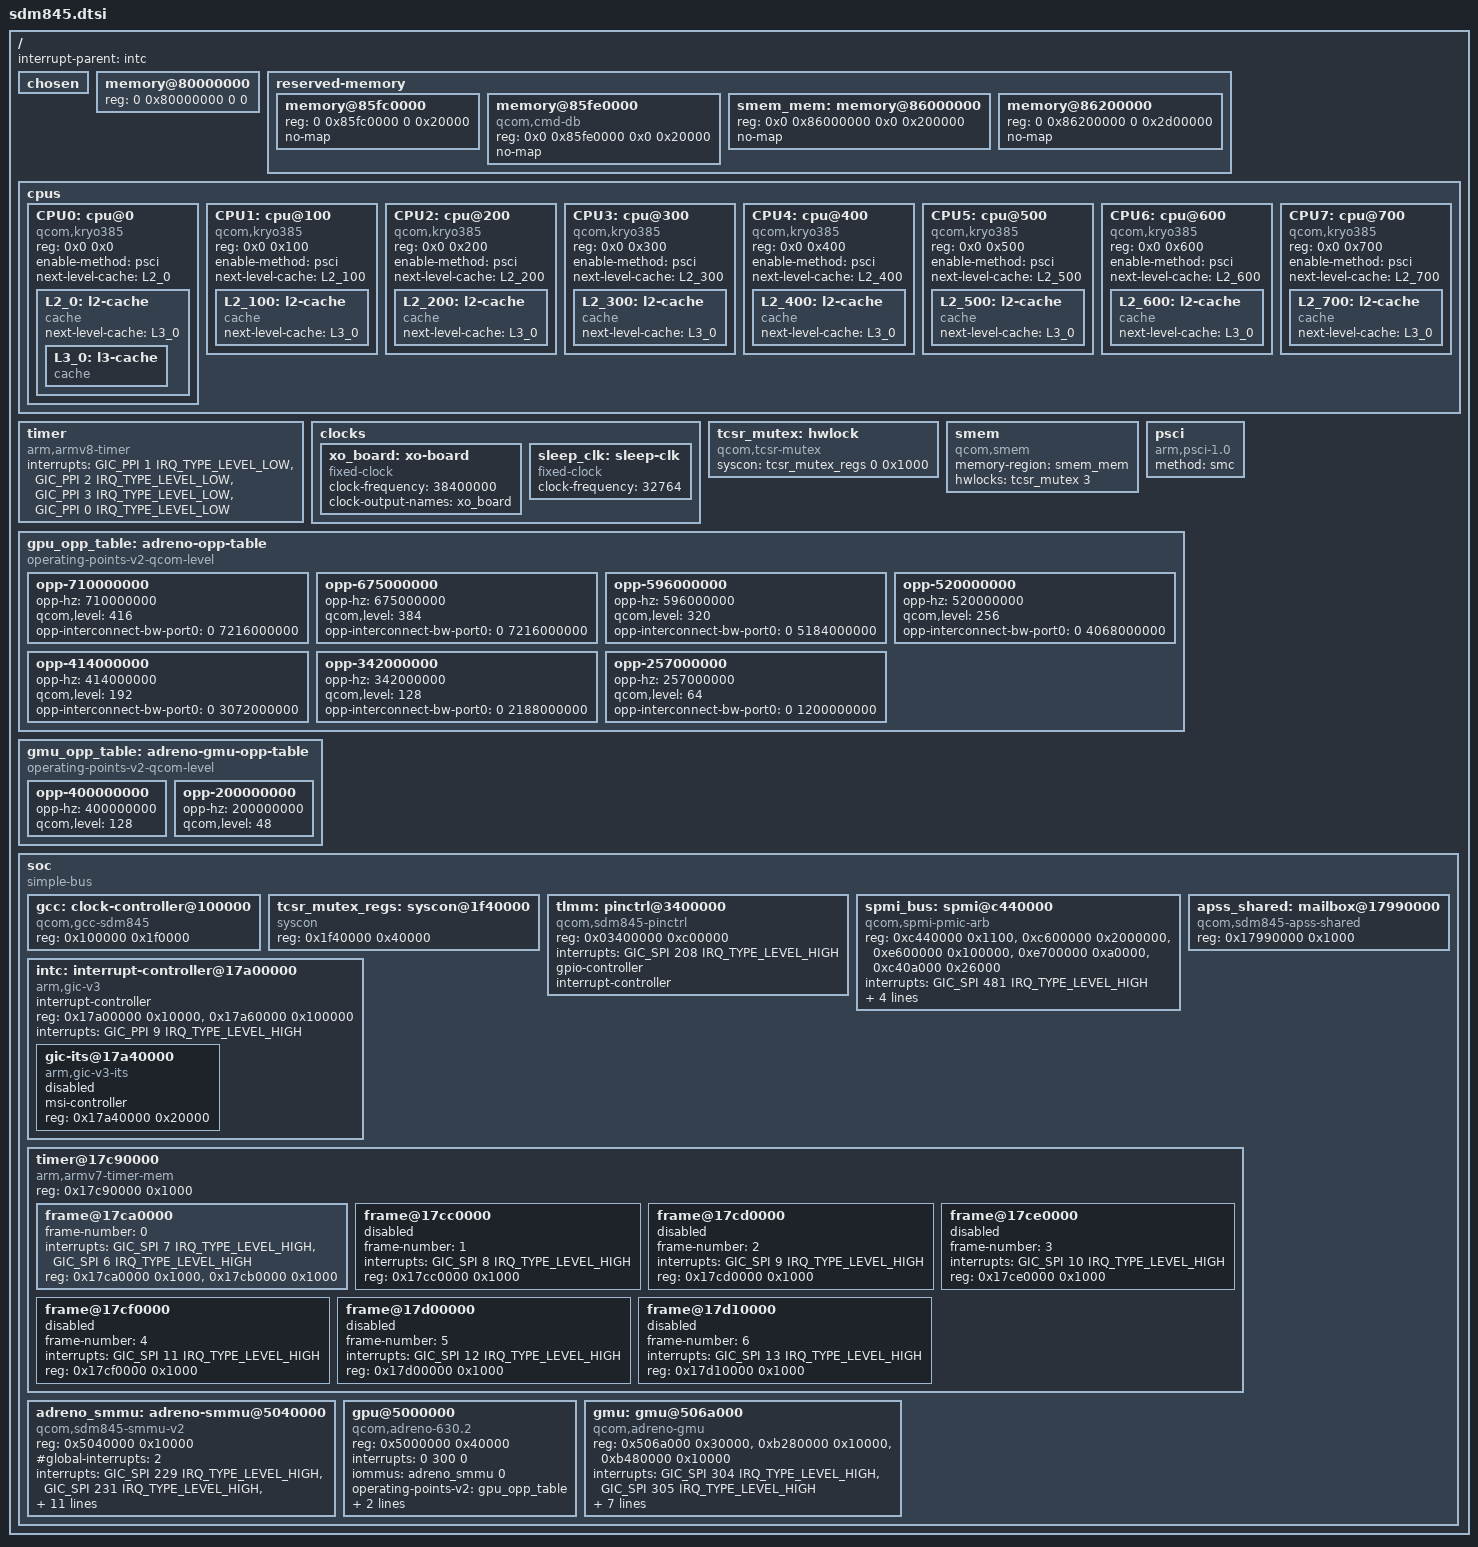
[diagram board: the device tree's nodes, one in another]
// SPDX-License-Identifier: GPL-2.0
/*
 * SDM845 SoC device tree source
 *
 * Copyright (c) 2018, The Linux Foundation. All rights reserved.
 */

#include <dt-bindings/interrupt-controller/arm-gic.h>

/ {
	interrupt-parent = <&intc>;

	#address-cells = <2>;
	#size-cells = <2>;

	chosen { };

	memory@80000000 {
		device_type = "memory";
		/* We expect the bootloader to fill in the size */
		reg = <0 0x80000000 0 0>;
	};

	reserved-memory {
		#address-cells = <2>;
		#size-cells = <2>;
		ranges;

		memory@85fc0000 {
			reg = <0 0x85fc0000 0 0x20000>;
			no-map;
		};

		memory@85fe0000 {
			compatible = "qcom,cmd-db";
			reg = <0x0 0x85fe0000 0x0 0x20000>;
			no-map;
		};

		smem_mem: memory@86000000 {
			reg = <0x0 0x86000000 0x0 0x200000>;
			no-map;
		};

		memory@86200000 {
			reg = <0 0x86200000 0 0x2d00000>;
			no-map;
		};
	};

	cpus {
		#address-cells = <2>;
		#size-cells = <0>;

		CPU0: cpu@0 {
			device_type = "cpu";
			compatible = "qcom,kryo385";
			reg = <0x0 0x0>;
			enable-method = "psci";
			next-level-cache = <&L2_0>;
			L2_0: l2-cache {
				compatible = "cache";
				next-level-cache = <&L3_0>;
				L3_0: l3-cache {
				      compatible = "cache";
				};
			};
		};

		CPU1: cpu@100 {
			device_type = "cpu";
			compatible = "qcom,kryo385";
			reg = <0x0 0x100>;
			enable-method = "psci";
			next-level-cache = <&L2_100>;
			L2_100: l2-cache {
				compatible = "cache";
				next-level-cache = <&L3_0>;
			};
		};

		CPU2: cpu@200 {
			device_type = "cpu";
			compatible = "qcom,kryo385";
			reg = <0x0 0x200>;
			enable-method = "psci";
			next-level-cache = <&L2_200>;
			L2_200: l2-cache {
				compatible = "cache";
				next-level-cache = <&L3_0>;
			};
		};

		CPU3: cpu@300 {
			device_type = "cpu";
			compatible = "qcom,kryo385";
			reg = <0x0 0x300>;
			enable-method = "psci";
			next-level-cache = <&L2_300>;
			L2_300: l2-cache {
				compatible = "cache";
				next-level-cache = <&L3_0>;
			};
		};

		CPU4: cpu@400 {
			device_type = "cpu";
			compatible = "qcom,kryo385";
			reg = <0x0 0x400>;
			enable-method = "psci";
			next-level-cache = <&L2_400>;
			L2_400: l2-cache {
				compatible = "cache";
				next-level-cache = <&L3_0>;
			};
		};

		CPU5: cpu@500 {
			device_type = "cpu";
			compatible = "qcom,kryo385";
			reg = <0x0 0x500>;
			enable-method = "psci";
			next-level-cache = <&L2_500>;
			L2_500: l2-cache {
				compatible = "cache";
				next-level-cache = <&L3_0>;
			};
		};

		CPU6: cpu@600 {
			device_type = "cpu";
			compatible = "qcom,kryo385";
			reg = <0x0 0x600>;
			enable-method = "psci";
			next-level-cache = <&L2_600>;
			L2_600: l2-cache {
				compatible = "cache";
				next-level-cache = <&L3_0>;
			};
		};

		CPU7: cpu@700 {
			device_type = "cpu";
			compatible = "qcom,kryo385";
			reg = <0x0 0x700>;
			enable-method = "psci";
			next-level-cache = <&L2_700>;
			L2_700: l2-cache {
				compatible = "cache";
				next-level-cache = <&L3_0>;
			};
		};
	};

	timer {
		compatible = "arm,armv8-timer";
		interrupts = <GIC_PPI 1 IRQ_TYPE_LEVEL_LOW>,
			     <GIC_PPI 2 IRQ_TYPE_LEVEL_LOW>,
			     <GIC_PPI 3 IRQ_TYPE_LEVEL_LOW>,
			     <GIC_PPI 0 IRQ_TYPE_LEVEL_LOW>;
	};

	clocks {
		xo_board: xo-board {
			compatible = "fixed-clock";
			#clock-cells = <0>;
			clock-frequency = <38400000>;
			clock-output-names = "xo_board";
		};

		sleep_clk: sleep-clk {
			compatible = "fixed-clock";
			#clock-cells = <0>;
			clock-frequency = <32764>;
		};
	};

	tcsr_mutex: hwlock {
		compatible = "qcom,tcsr-mutex";
		syscon = <&tcsr_mutex_regs 0 0x1000>;
		#hwlock-cells = <1>;
	};

	smem {
		compatible = "qcom,smem";
		memory-region = <&smem_mem>;
		hwlocks = <&tcsr_mutex 3>;
	};

	psci {
		compatible = "arm,psci-1.0";
		method = "smc";
	};

gpu_opp_table: adreno-opp-table {
		compatible = "operating-points-v2-qcom-level";

		opp-710000000 {
			opp-hz = /bits/ 64 <710000000>;
			qcom,level = <416>;
			opp-interconnect-bw-port0 = /bits/ 64 <0 7216000000>;
		};

		opp-675000000 {
			opp-hz = /bits/ 64 <675000000>;
			qcom,level = <384>;
			opp-interconnect-bw-port0 = /bits/ 64 <0 7216000000>;
		};

		opp-596000000 {
			opp-hz = /bits/ 64 <596000000>;
			qcom,level = <320>;
			opp-interconnect-bw-port0 = /bits/ 64 <0 5184000000>;
		};

		opp-520000000 {
			opp-hz = /bits/ 64 <520000000>;
			qcom,level = <256>;
			opp-interconnect-bw-port0 = /bits/ 64 <0 4068000000>;
		};

		opp-414000000 {
			opp-hz = /bits/ 64 <414000000>;
			qcom,level = <192>;
			opp-interconnect-bw-port0 = /bits/ 64 <0 3072000000>;
		};

		opp-342000000 {
			opp-hz = /bits/ 64 <342000000>;
			qcom,level = <128>;
			opp-interconnect-bw-port0 = /bits/ 64 <0 2188000000>;
		};

		opp-257000000 {
			opp-hz = /bits/ 64 <257000000>;
			qcom,level = <64>;
			opp-interconnect-bw-port0 = /bits/ 64 <0 1200000000>;
		};
	};

	gmu_opp_table: adreno-gmu-opp-table {
		compatible = "operating-points-v2-qcom-level";

		opp-400000000 {
			opp-hz = /bits/ 64 <400000000>;
			qcom,level = <128>;
		};

		opp-200000000 {
			opp-hz = /bits/ 64 <200000000>;
			qcom,level = <48>;
		};
	};

	soc: soc {
		#address-cells = <1>;
		#size-cells = <1>;
		ranges = <0 0 0 0xffffffff>;
		compatible = "simple-bus";

		gcc: clock-controller@100000 {
			compatible = "qcom,gcc-sdm845";
			reg = <0x100000 0x1f0000>;
			#clock-cells = <1>;
			#reset-cells = <1>;
			#power-domain-cells = <1>;
		};

		tcsr_mutex_regs: syscon@1f40000 {
			compatible = "syscon";
			reg = <0x1f40000 0x40000>;
		};

		tlmm: pinctrl@3400000 {
			compatible = "qcom,sdm845-pinctrl";
			reg = <0x03400000 0xc00000>;
			interrupts = <GIC_SPI 208 IRQ_TYPE_LEVEL_HIGH>;
			gpio-controller;
			#gpio-cells = <2>;
			interrupt-controller;
			#interrupt-cells = <2>;
		};

		spmi_bus: spmi@c440000 {
			compatible = "qcom,spmi-pmic-arb";
			reg = <0xc440000 0x1100>,
			      <0xc600000 0x2000000>,
			      <0xe600000 0x100000>,
			      <0xe700000 0xa0000>,
			      <0xc40a000 0x26000>;
			reg-names = "core", "chnls", "obsrvr", "intr", "cnfg";
			interrupt-names = "periph_irq";
			interrupts = <GIC_SPI 481 IRQ_TYPE_LEVEL_HIGH>;
			qcom,ee = <0>;
			qcom,channel = <0>;
			#address-cells = <2>;
			#size-cells = <0>;
			interrupt-controller;
			#interrupt-cells = <4>;
			cell-index = <0>;
		};

		apss_shared: mailbox@17990000 {
			compatible = "qcom,sdm845-apss-shared";
			reg = <0x17990000 0x1000>;
			#mbox-cells = <1>;
		};

		intc: interrupt-controller@17a00000 {
			compatible = "arm,gic-v3";
			#address-cells = <1>;
			#size-cells = <1>;
			ranges;
			#interrupt-cells = <3>;
			interrupt-controller;
			reg = <0x17a00000 0x10000>,     /* GICD */
			      <0x17a60000 0x100000>;    /* GICR * 8 */
			interrupts = <GIC_PPI 9 IRQ_TYPE_LEVEL_HIGH>;

			gic-its@17a40000 {
				compatible = "arm,gic-v3-its";
				msi-controller;
				#msi-cells = <1>;
				reg = <0x17a40000 0x20000>;
				status = "disabled";
			};
		};

		timer@17c90000 {
			#address-cells = <1>;
			#size-cells = <1>;
			ranges;
			compatible = "arm,armv7-timer-mem";
			reg = <0x17c90000 0x1000>;

			frame@17ca0000 {
				frame-number = <0>;
				interrupts = <GIC_SPI 7 IRQ_TYPE_LEVEL_HIGH>,
					     <GIC_SPI 6 IRQ_TYPE_LEVEL_HIGH>;
				reg = <0x17ca0000 0x1000>,
				      <0x17cb0000 0x1000>;
			};

			frame@17cc0000 {
				frame-number = <1>;
				interrupts = <GIC_SPI 8 IRQ_TYPE_LEVEL_HIGH>;
				reg = <0x17cc0000 0x1000>;
				status = "disabled";
			};

			frame@17cd0000 {
				frame-number = <2>;
				interrupts = <GIC_SPI 9 IRQ_TYPE_LEVEL_HIGH>;
				reg = <0x17cd0000 0x1000>;
				status = "disabled";
			};

			frame@17ce0000 {
				frame-number = <3>;
				interrupts = <GIC_SPI 10 IRQ_TYPE_LEVEL_HIGH>;
				reg = <0x17ce0000 0x1000>;
				status = "disabled";
			};

			frame@17cf0000 {
				frame-number = <4>;
				interrupts = <GIC_SPI 11 IRQ_TYPE_LEVEL_HIGH>;
				reg = <0x17cf0000 0x1000>;
				status = "disabled";
			};

			frame@17d00000 {
				frame-number = <5>;
				interrupts = <GIC_SPI 12 IRQ_TYPE_LEVEL_HIGH>;
				reg = <0x17d00000 0x1000>;
				status = "disabled";
			};

			frame@17d10000 {
				frame-number = <6>;
				interrupts = <GIC_SPI 13 IRQ_TYPE_LEVEL_HIGH>;
				reg = <0x17d10000 0x1000>;
				status = "disabled";
			};
		};

		adreno_smmu: adreno-smmu@5040000 {
			compatible = "qcom,sdm845-smmu-v2", "qcom,smmu-v2";
			reg = <0x5040000 0x10000>;
			#iommu-cells = <1>;
			#global-interrupts = <2>;
			interrupts = <GIC_SPI 229 IRQ_TYPE_LEVEL_HIGH>,
					<GIC_SPI 231 IRQ_TYPE_LEVEL_HIGH>,
					<GIC_SPI 364 IRQ_TYPE_EDGE_RISING>,
					<GIC_SPI 365 IRQ_TYPE_EDGE_RISING>,
					<GIC_SPI 366 IRQ_TYPE_EDGE_RISING>,
					<GIC_SPI 367 IRQ_TYPE_EDGE_RISING>,
					<GIC_SPI 368 IRQ_TYPE_EDGE_RISING>,
					<GIC_SPI 369 IRQ_TYPE_EDGE_RISING>,
					<GIC_SPI 370 IRQ_TYPE_EDGE_RISING>,
					<GIC_SPI 371 IRQ_TYPE_EDGE_RISING>;
			clocks = <&gcc GCC_GPU_MEMNOC_GFX_CLK>,
				<&gcc GCC_GPU_CFG_AHB_CLK>;
			clock-names = "bus", "iface";

			power-domains = <&gpucc GPU_CX_GDSC>;
		};

		gpu@5000000 {
			compatible = "qcom,adreno-630.2", "qcom,adreno";
			#stream-id-cells = <16>;

			reg = <0x5000000 0x40000>;
			reg-names = "kgsl_3d0_reg_memory";

			/*
			 * Look ma, no clocks! The GPU clocks and power are
			 * controlled entirely by the GMU
			 */

			interrupts = <0 300 0>;
			interrupt-names = "kgsl_3d0_irq";

			iommus = <&adreno_smmu 0>;

			operating-points-v2 = <&gpu_opp_table>;

			interconnects = <&qnoc 26 &qnoc 512>;
			interconnect-names = "port0";

			qcom,gmu = <&gmu>;
		};

		gmu: gmu@506a000 {
			compatible="qcom,adreno-gmu";

			reg = <0x506a000 0x30000>,
				<0xb280000 0x10000>,
				<0xb480000 0x10000>;
			reg-names = "gmu", "gmu_pdc", "gmu_pdc_seq";

			interrupts = <GIC_SPI 304 IRQ_TYPE_LEVEL_HIGH>,
			     <GIC_SPI 305 IRQ_TYPE_LEVEL_HIGH>;
			interrupt-names = "hfi", "gmu";

			clocks = <&gpucc GPU_CC_CX_GMU_CLK>,
				<&gpucc GPU_CC_CXO_CLK>,
				<&gcc GCC_DDRSS_GPU_AXI_CLK>,
				<&gcc GCC_GPU_MEMNOC_GFX_CLK>;
			clock-names = "gmu", "cxo", "axi", "memnoc";

			power-domains = <&gpucc GPU_CX_GDSC>;
			iommus = <&adreno_smmu 5>;

			operating-points-v2 = <&gmu_opp_table>;
		};
	};
};
